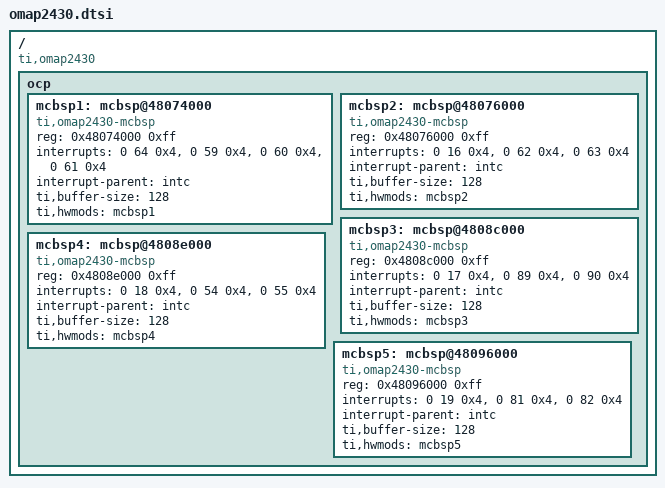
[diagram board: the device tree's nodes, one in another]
/*
 * Device Tree Source for OMAP243x SoC
 *
 * Copyright (C) 2011 Texas Instruments Incorporated - http://www.ti.com/
 *
 * This file is licensed under the terms of the GNU General Public License
 * version 2.  This program is licensed "as is" without any warranty of any
 * kind, whether express or implied.
 */

/include/ "omap2.dtsi"

/ {
	compatible = "ti,omap2430", "ti,omap2";

	ocp {
		mcbsp1: mcbsp@48074000 {
			compatible = "ti,omap2430-mcbsp";
			reg = <0x48074000 0xff>;
			reg-names = "mpu";
			interrupts = <0 64 0x4>, /* OCP compliant interrupt */
				     <0 59 0x4>, /* TX interrupt */
				     <0 60 0x4>, /* RX interrupt */
				     <0 61 0x4>; /* RX overflow interrupt */
			interrupt-names = "common", "tx", "rx", "rx_overflow";
			interrupt-parent = <&intc>;
			ti,buffer-size = <128>;
			ti,hwmods = "mcbsp1";
		};

		mcbsp2: mcbsp@48076000 {
			compatible = "ti,omap2430-mcbsp";
			reg = <0x48076000 0xff>;
			reg-names = "mpu";
			interrupts = <0 16 0x4>, /* OCP compliant interrupt */
				     <0 62 0x4>, /* TX interrupt */
				     <0 63 0x4>; /* RX interrupt */
			interrupt-names = "common", "tx", "rx";
			interrupt-parent = <&intc>;
			ti,buffer-size = <128>;
			ti,hwmods = "mcbsp2";
		};

		mcbsp3: mcbsp@4808c000 {
			compatible = "ti,omap2430-mcbsp";
			reg = <0x4808c000 0xff>;
			reg-names = "mpu";
			interrupts = <0 17 0x4>, /* OCP compliant interrupt */
				     <0 89 0x4>, /* TX interrupt */
				     <0 90 0x4>; /* RX interrupt */
			interrupt-names = "common", "tx", "rx";
			interrupt-parent = <&intc>;
			ti,buffer-size = <128>;
			ti,hwmods = "mcbsp3";
		};

		mcbsp4: mcbsp@4808e000 {
			compatible = "ti,omap2430-mcbsp";
			reg = <0x4808e000 0xff>;
			reg-names = "mpu";
			interrupts = <0 18 0x4>, /* OCP compliant interrupt */
				     <0 54 0x4>, /* TX interrupt */
				     <0 55 0x4>; /* RX interrupt */
			interrupt-names = "common", "tx", "rx";
			interrupt-parent = <&intc>;
			ti,buffer-size = <128>;
			ti,hwmods = "mcbsp4";
		};

		mcbsp5: mcbsp@48096000 {
			compatible = "ti,omap2430-mcbsp";
			reg = <0x48096000 0xff>;
			reg-names = "mpu";
			interrupts = <0 19 0x4>, /* OCP compliant interrupt */
				     <0 81 0x4>, /* TX interrupt */
				     <0 82 0x4>; /* RX interrupt */
			interrupt-names = "common", "tx", "rx";
			interrupt-parent = <&intc>;
			ti,buffer-size = <128>;
			ti,hwmods = "mcbsp5";
		};
	};
};
